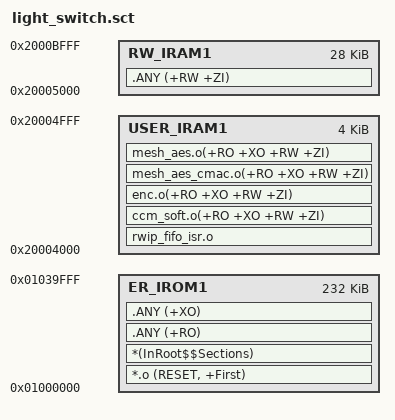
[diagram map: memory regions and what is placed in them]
; *************************************************************
; *** Scatter-Loading Description File generated by uVision ***
; *************************************************************

LR_IROM1 0x01000000 0x0003A000  {    ; load region size_region
  ER_IROM1 0x01000000 0x0003A000  {  ; load address = execution address
   *.o (RESET, +First)
   *(InRoot$$Sections)
   .ANY (+RO)
   .ANY (+XO)
  }
  
  USER_IRAM1 0x20004000 0x00001000  {  ; RW data
    rwip_fifo_isr.o
    ccm_soft.o(+RO +XO +RW +ZI) ; 
    enc.o(+RO +XO +RW +ZI) ; 
    mesh_aes_cmac.o(+RO +XO +RW +ZI) ; 
    mesh_aes.o(+RO +XO +RW +ZI) ; 
  }    



  RW_IRAM1 0x20005000 0x00007000  {  ; RW data
   .ANY (+RW +ZI)
  }
}

